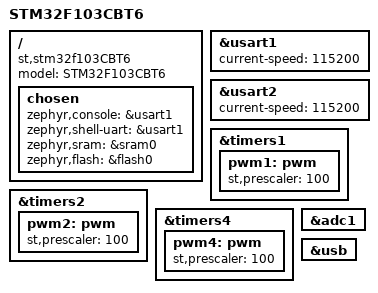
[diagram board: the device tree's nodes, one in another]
/*
 * Copyright (c) 2017, embedjournal.com
 *
 * SPDX-License-Identifier: Apache-2.0
 */

/dts-v1/;
#include <st/f1/stm32f103Xb.dtsi>

/ {
	model = "STM32F103CBT6";
	compatible = "st,stm32f103CBT6", "st,stm32f103cb";

	chosen {
		zephyr,console = &usart1;
		zephyr,shell-uart = &usart1;
		zephyr,sram = &sram0;
		zephyr,flash = &flash0;
	};
};


&usart1 {
	current-speed = <115200>;
	status = "okay";
};

&usart2 {
	current-speed = <115200>;
	status = "okay";
};

&timers1 {
	status = "okay";

	pwm1: pwm {
		status = "okay";
		st,prescaler = <100>;
	};
};

&timers2 {
	status = "okay";

	pwm2: pwm {
		status = "okay";
		st,prescaler = <100>;
	};
};

&timers4 {
	status = "okay";

	pwm4: pwm {
		status = "okay";
		st,prescaler = <100>;
	};
};

&adc1 {
	status = "okay";
};

&usb {
	status = "okay";
};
